# N32MC47x_DP47x register map
Vendor: Nsingtech Ltd.; File version: 1.0
Registers are 32-bit, read-write, reset 0x0 unless marked. A register's access mark holds for its fields unless they carry their own. Offsets are from the block's base; [hi:lo] are bit positions; {n}, {i} and the like mark numbered series.

## GPIOA — General purpose I/O
Base 0x4002C000
Same registers: GPIOB 0x4002C400, GPIOC 0x4002C800, GPIOD 0x4002CC00, GPIOE 0x4002D000
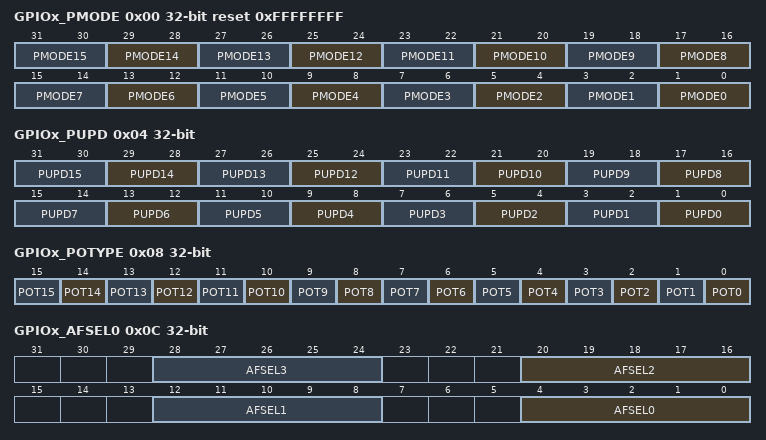
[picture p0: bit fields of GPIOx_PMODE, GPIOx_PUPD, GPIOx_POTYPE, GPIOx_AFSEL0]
0x00 GPIOx_PMODE reset 0xFFFFFFFF — GPIO mode description register
  [2n+1:2n] PMODE{n} (n=0..15)
0x04 GPIOx_PUPD — GPIO pull-up/pull-down description register
  [2n+1:2n] PUPD{n} (n=0..15)
0x08 GPIOx_POTYPE — GPIO output type definition
  [n] POT{n} (n=0..15)
0x0C GPIOx_AFSEL0 — GPIO alternate function select register 0
  [8n+4:8n] AFSEL{n} (n=0..3)
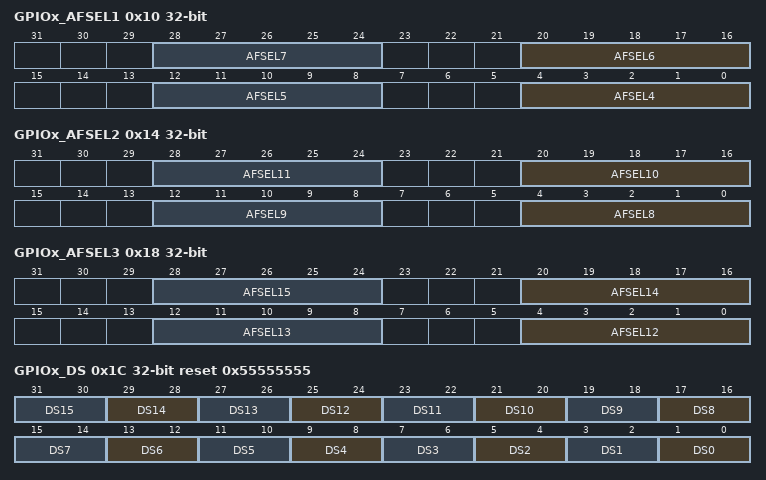
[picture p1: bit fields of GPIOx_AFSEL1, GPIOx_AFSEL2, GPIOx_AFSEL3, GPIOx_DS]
0x10 GPIOx_AFSEL1 — GPIO alternate function select register 1
  [8n-28:8n-32] AFSEL{n} (n=4..7)
0x14 GPIOx_AFSEL2 — GPIO alternate function select register 2
  [8n-60:8n-64] AFSEL{n} (n=8..11)
0x18 GPIOx_AFSEL3 — GPIO alternate function select register 3
  [8n-92:8n-96] AFSEL{n} (n=12..15)
0x1C GPIOx_DS reset 0x55555555 — GPIO driver strength configuration register
  [2n+1:2n] DS{n} (n=0..15)
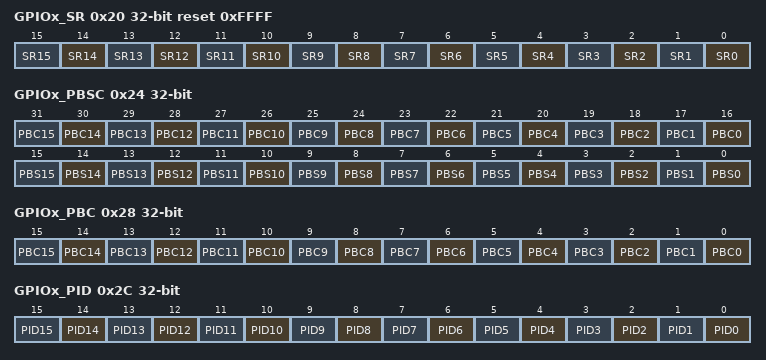
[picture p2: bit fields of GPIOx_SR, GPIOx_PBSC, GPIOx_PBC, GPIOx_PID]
0x20 GPIOx_SR reset 0xFFFF — GPIO slew rate configuration register
  [n] SR{n} (n=0..15)
0x24 GPIOx_PBSC wo — GPIO bit set/clear register
  [n+16] PBC{n} (n=0..15), [n] PBS{n} (n=0..15)
0x28 GPIOx_PBC wo — GPIO bit clear register
  [n] PBC{n} (n=0..15)
0x2C GPIOx_PID ro — GPIO input data register
  [n] PID{n} (n=0..15)
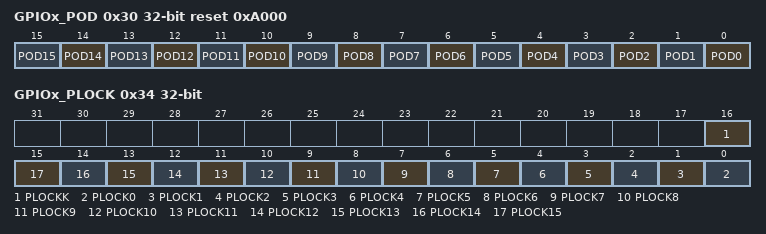
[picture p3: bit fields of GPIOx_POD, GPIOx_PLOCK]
0x30 GPIOx_POD reset 0xA000 — GPIO output data register
  [n] POD{n} (n=0..15)
0x34 GPIOx_PLOCK — GPIO configuration lock register
  [16] PLOCKK, [n] PLOCK{n} (n=0..15)

## GPIOF — General purpose I/O
Base 0x4002D400
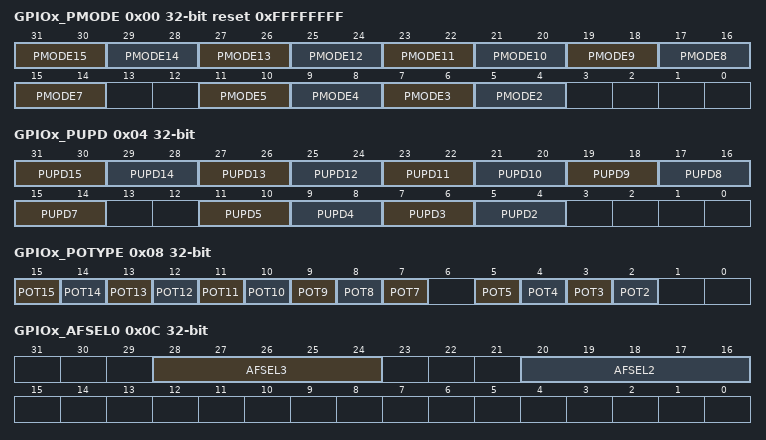
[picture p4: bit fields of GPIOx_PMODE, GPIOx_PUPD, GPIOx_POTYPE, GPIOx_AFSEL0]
0x00 GPIOx_PMODE reset 0xFFFFFFFF — GPIO mode description register
  [2n+1:2n] PMODE{n} (n=7..15), [2n+1:2n] PMODE{n} (n=2..5)
0x04 GPIOx_PUPD — GPIO pull-up/pull-down description register
  [2n+1:2n] PUPD{n} (n=7..15), [2n+1:2n] PUPD{n} (n=2..5)
0x08 GPIOx_POTYPE — GPIO output type definition
  [n] POT{n} (n=7..15), [n] POT{n} (n=2..5)
0x0C GPIOx_AFSEL0 — GPIO alternate function select register 0
  [28:24] AFSEL3, [20:16] AFSEL2
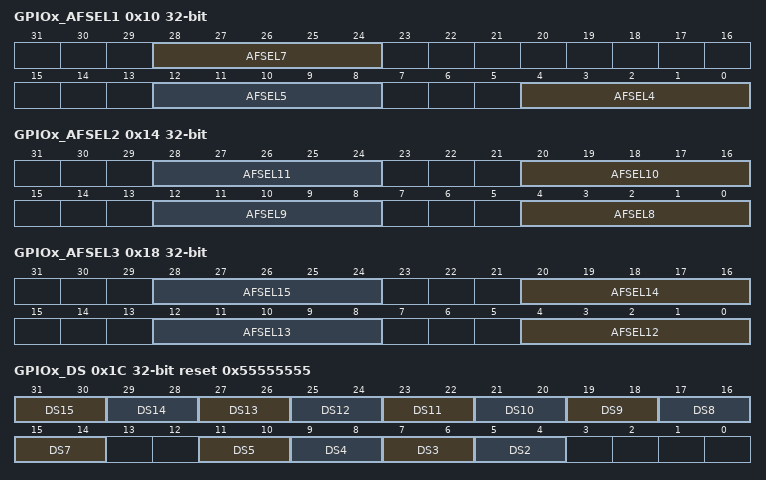
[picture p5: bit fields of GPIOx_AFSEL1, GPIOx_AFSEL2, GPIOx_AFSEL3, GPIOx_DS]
0x10 GPIOx_AFSEL1 — GPIO alternate function select register 1
  [28:24] AFSEL7, [12:8] AFSEL5, [4:0] AFSEL4
0x14 GPIOx_AFSEL2 — GPIO alternate function select register 2
  [8n-60:8n-64] AFSEL{n} (n=8..11)
0x18 GPIOx_AFSEL3 — GPIO alternate function select register 3
  [8n-92:8n-96] AFSEL{n} (n=12..15)
0x1C GPIOx_DS reset 0x55555555 — GPIO driver strength configuration register
  [2n+1:2n] DS{n} (n=7..15), [2n+1:2n] DS{n} (n=2..5)
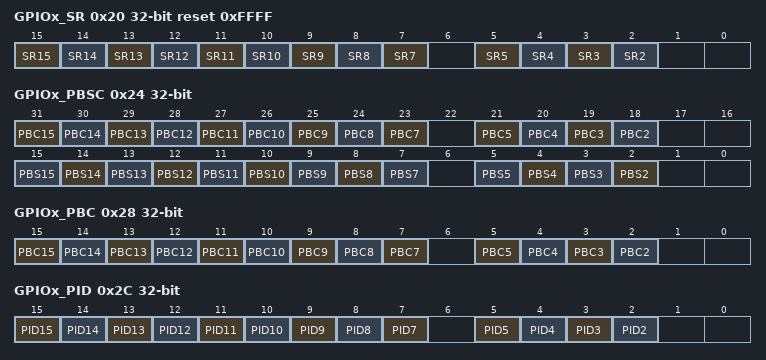
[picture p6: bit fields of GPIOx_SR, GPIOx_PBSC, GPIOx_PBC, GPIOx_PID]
0x20 GPIOx_SR reset 0xFFFF — GPIO slew rate configuration register
  [n] SR{n} (n=7..15), [n] SR{n} (n=2..5)
0x24 GPIOx_PBSC wo — GPIO bit set/clear register
  [n+16] PBC{n} (n=7..15), [n+16] PBC{n} (n=2..5), [n] PBS{n} (n=7..15), [n] PBS{n} (n=2..5)
0x28 GPIOx_PBC wo — GPIO bit clear register
  [n] PBC{n} (n=7..15), [n] PBC{n} (n=2..5)
0x2C GPIOx_PID ro — GPIO input data register
  [n] PID{n} (n=7..15), [n] PID{n} (n=2..5)
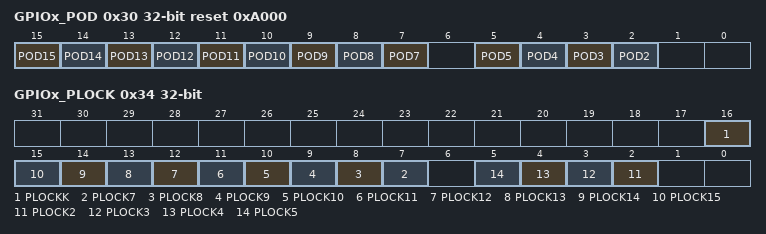
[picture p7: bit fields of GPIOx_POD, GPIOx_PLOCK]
0x30 GPIOx_POD reset 0xA000 — GPIO output data register
  [n] POD{n} (n=7..15), [n] POD{n} (n=2..5)
0x34 GPIOx_PLOCK — GPIO configuration lock register
  [16] PLOCKK, [n] PLOCK{n} (n=7..15), [n] PLOCK{n} (n=2..5)

## GPIOG — General purpose I/O
Base 0x4002D800
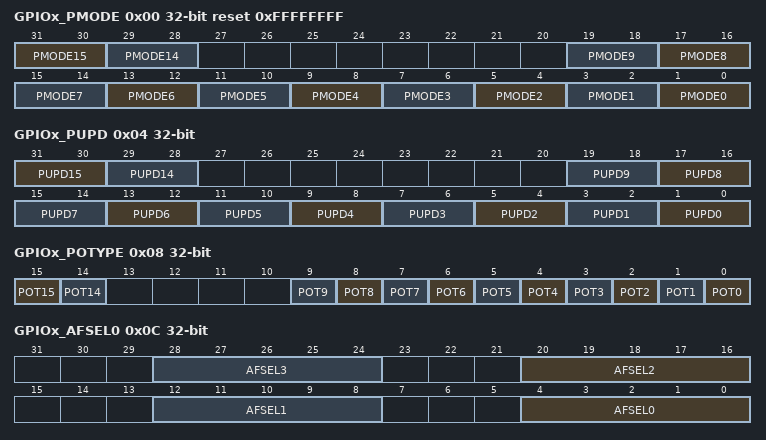
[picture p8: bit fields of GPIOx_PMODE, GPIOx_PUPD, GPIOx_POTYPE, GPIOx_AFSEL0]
0x00 GPIOx_PMODE reset 0xFFFFFFFF — GPIO mode description register
  [31:30] PMODE15, [29:28] PMODE14, [2n+1:2n] PMODE{n} (n=0..9)
0x04 GPIOx_PUPD — GPIO pull-up/pull-down description register
  [31:30] PUPD15, [29:28] PUPD14, [2n+1:2n] PUPD{n} (n=0..9)
0x08 GPIOx_POTYPE — GPIO output type definition
  [15] POT15, [14] POT14, [n] POT{n} (n=0..9)
0x0C GPIOx_AFSEL0 — GPIO alternate function select register 0
  [8n+4:8n] AFSEL{n} (n=0..3)
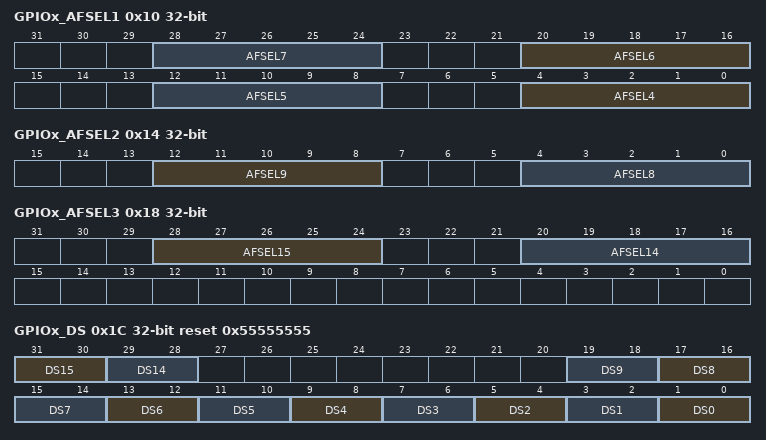
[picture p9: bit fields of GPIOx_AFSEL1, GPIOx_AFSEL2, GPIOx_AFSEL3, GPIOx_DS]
0x10 GPIOx_AFSEL1 — GPIO alternate function select register 1
  [8n-28:8n-32] AFSEL{n} (n=4..7)
0x14 GPIOx_AFSEL2 — GPIO alternate function select register 2
  [12:8] AFSEL9, [4:0] AFSEL8
0x18 GPIOx_AFSEL3 — GPIO alternate function select register 3
  [28:24] AFSEL15, [20:16] AFSEL14
0x1C GPIOx_DS reset 0x55555555 — GPIO driver strength configuration register
  [31:30] DS15, [29:28] DS14, [2n+1:2n] DS{n} (n=0..9)
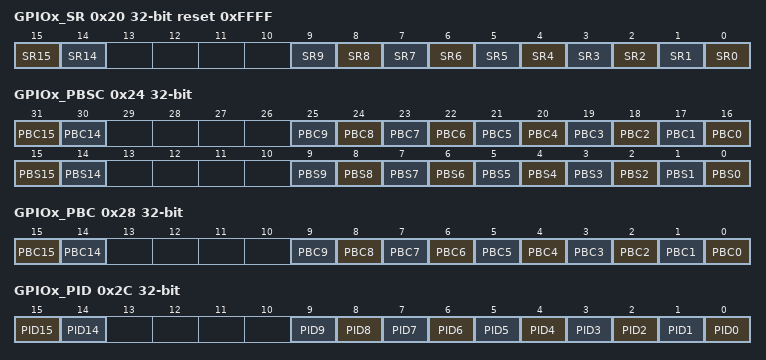
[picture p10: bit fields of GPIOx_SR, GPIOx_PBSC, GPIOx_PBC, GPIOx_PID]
0x20 GPIOx_SR reset 0xFFFF — GPIO slew rate configuration register
  [15] SR15, [14] SR14, [n] SR{n} (n=0..9)
0x24 GPIOx_PBSC wo — GPIO bit set/clear register
  [31] PBC15, [30] PBC14, [n+16] PBC{n} (n=0..9), [15] PBS15, [14] PBS14, [n] PBS{n} (n=0..9)
0x28 GPIOx_PBC wo — GPIO bit clear register
  [15] PBC15, [14] PBC14, [n] PBC{n} (n=0..9)
0x2C GPIOx_PID ro — GPIO input data register
  [15] PID15, [14] PID14, [n] PID{n} (n=0..9)
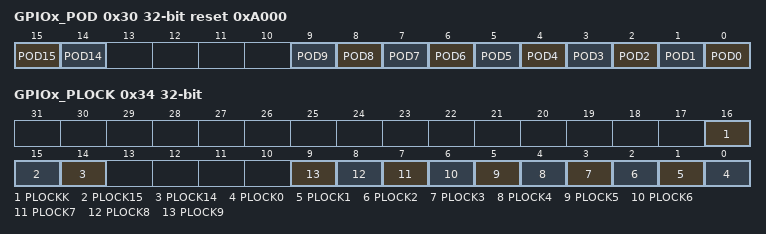
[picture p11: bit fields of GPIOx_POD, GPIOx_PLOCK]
0x30 GPIOx_POD reset 0xA000 — GPIO output data register
  [15] POD15, [14] POD14, [n] POD{n} (n=0..9)
0x34 GPIOx_PLOCK — GPIO configuration lock register
  [16] PLOCKK, [15] PLOCK15, [14] PLOCK14, [n] PLOCK{n} (n=0..9)
